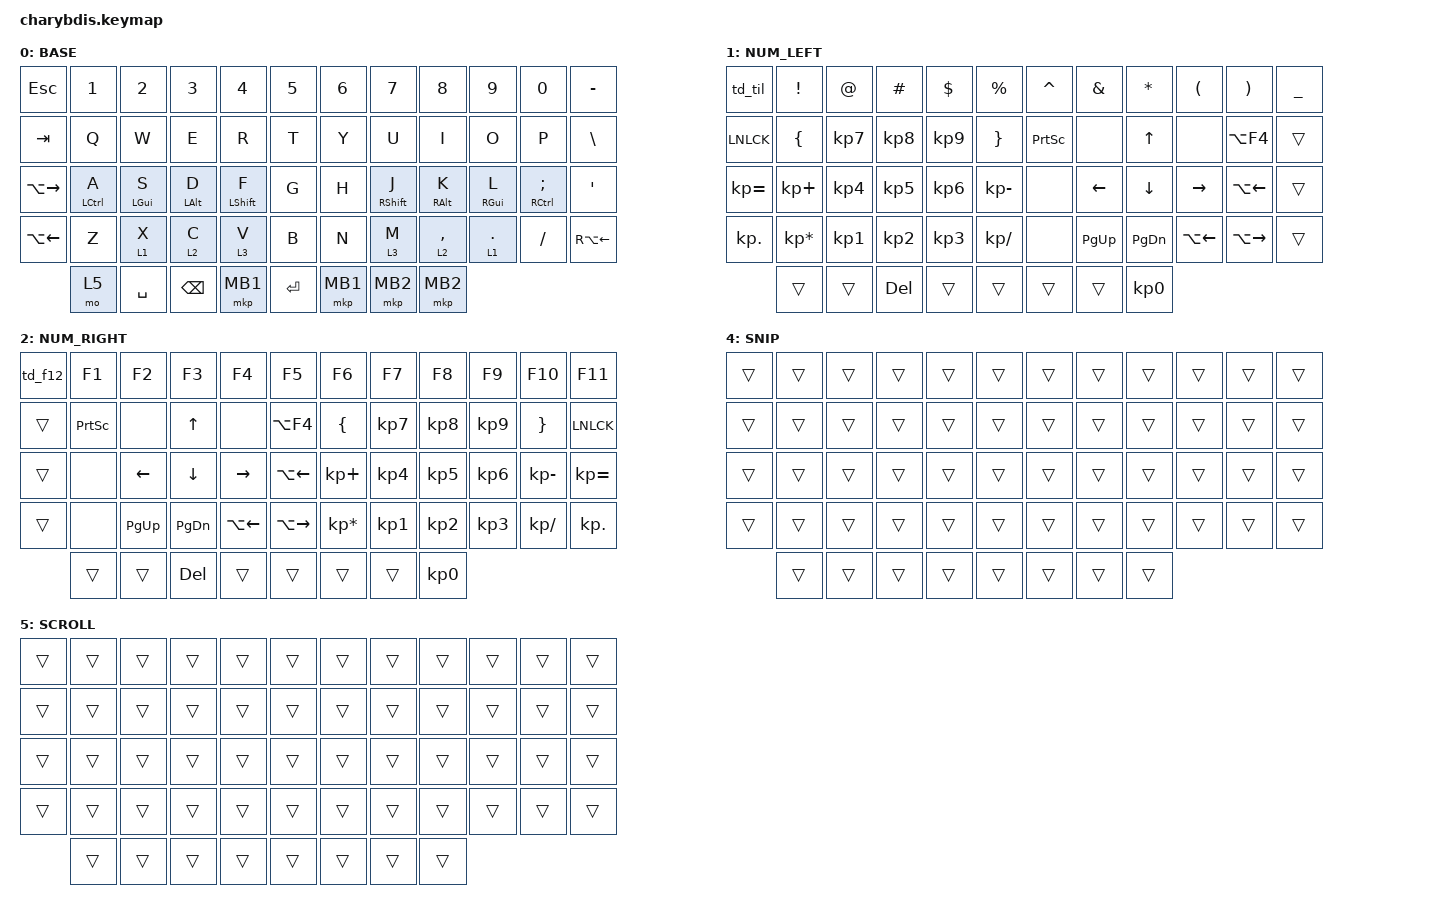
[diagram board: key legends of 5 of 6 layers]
#include <behaviors.dtsi>
#include <dt-bindings/zmk/bt.h>
#include <dt-bindings/zmk/keys.h>
#include <dt-bindings/zmk/outputs.h>
#include <dt-bindings/zmk/pointing.h>
#include <dt-bindings/zmk/input_transform.h>
#include <input/processors.dtsi>

/* Global settings */
&mt {
    quick-tap-ms = <200>;
    flavor = "tap-preferred";
    tapping-term-ms = <170>;
};

&lt {
    quick-tap-ms = <200>;
    flavor = "tap-preferred";
    tapping-term-ms = <170>;
};

/ {
    chosen { zmk,matrix_transform = &default_transform; };

    macros {
        endash: endash {
            compatible = "zmk,behavior-macro";
            #binding-cells = <0>;
            wait-ms = <10>;
            tap-ms = <10>;
            bindings
                = <&macro_press &kp LALT>
                , <&macro_tap &kp KP_N0 &kp KP_N1 &kp KP_N5 &kp KP_N0>
                , <&macro_release &kp LALT>;
        };
    };

    behaviors {
        td_esc: td_esc {
            compatible = "zmk,behavior-tap-dance";
            #binding-cells = <0>;
            tapping-term-ms = <200>;
            bindings = <&kp ESC>, <&to 0>;
        };
        td_til: td_til {
            compatible = "zmk,behavior-tap-dance";
            #binding-cells = <0>;
            tapping-term-ms = <200>;
            bindings = <&kp TILD>, <&to 0>;
        };
        td_f12: td_f12 {
            compatible = "zmk,behavior-tap-dance";
            #binding-cells = <0>;
            tapping-term-ms = <200>;
            bindings = <&kp F12>, <&to 0>;
        };
    };

    combos {
        compatible = "zmk,combos";
        combo_to_layer_1 {
            timeout-ms = <50>;
            key-positions = <38 45>; 
            bindings = <&to 1>;
        };
        combo_to_layer_2 {
            timeout-ms = <50>;
            key-positions = <39 44>; 
            bindings = <&to 2>;
        };
        combo_to_layer_3 {
            timeout-ms = <50>;
            key-positions = <40 43>; 
            bindings = <&to 3>;
        };
    };

#ifdef KEYMAP_DRAW_TRACKBALL
    trackball_listener {
        compatible = "zmk,input-listener";
        device = <&trackball>;
        snipe_override {
            layers = <4>;
            input-processors = <&zip_xy_scaler 1 2>; 
        };
        scroll_override {
            layers = <5>;
            input-processors = <&zip_xy_to_scroll_mapper>;
        };
    };
#endif

    keymap {
        compatible = "zmk,keymap";

        BASE {
            bindings = <
&kp ESC  &kp N1  &kp N2  &kp N3  &kp N4  &kp N5      &kp N6  &kp N7  &kp N8  &kp N9   &kp N0  &kp MINUS
&kp TAB  &kp Q  &kp W  &kp E  &kp R  &kp T      &kp Y  &kp U  &kp I  &kp O  &kp P  &kp BSLH
&kp LA(RIGHT)  &mt LCTRL A  &mt LGUI S  &mt LALT D  &mt LSHIFT F  &kp G      &kp H  &mt RSHIFT J  &mt RALT K  &mt RGUI L  &mt RCTRL SEMI  &kp APOS
&kp LA(LEFT)  &kp Z  &lt 1 X  &lt 2 C  &lt 3 V  &kp B      &kp N  &lt 3 M  &lt 2 COMMA  &lt 1 DOT  &kp SLASH  &kp RA(LEFT)
            &mo 5  &kp SPACE  &kp BSPC  &mkp MB1  &kp ENTER      &mkp MB1  &mkp MB2  &mkp MB2
            >;
        };

        NUM_LEFT {
            bindings = <
&td_til    &kp EXCL    &kp AT      &kp HASH    &kp DLLR    &kp PRCNT   &kp CARET   &kp AMPS    &kp ASTRK   &kp LPAR    &kp RPAR    &kp UNDER
&kp LNLCK  &kp LBRC    &kp KP_N7   &kp KP_N8   &kp KP_N9   &kp RBRC    &kp PSCRN   &none       &kp UP      &none       &kp LA(F4)  &trans
&kp KP_EQUAL &kp KP_PLUS &kp KP_N4 &kp KP_N5   &kp KP_N6   &kp KP_MINUS &none      &kp LEFT    &kp DOWN    &kp RIGHT   &kp LA(LEFT) &trans
&kp KP_DOT &kp KP_MULTIPLY &kp KP_N1 &kp KP_N2 &kp KP_N3   &kp KP_DIVIDE &none     &kp PG_UP   &kp PG_DN   &kp LA(LEFT) &kp LA(RIGHT) &trans
           &trans      &trans      &kp DEL     &trans      &trans      &trans      &trans      &kp KP_N0
            >;
        };

        NUM_RIGHT {
            bindings = <
&td_f12    &kp F1      &kp F2      &kp F3      &kp F4      &kp F5      &kp F6      &kp F7      &kp F8      &kp F9      &kp F10     &kp F11
&trans     &kp PSCRN   &none       &kp UP      &none       &kp LA(F4)  &kp LBRC    &kp KP_N7   &kp KP_N8   &kp KP_N9   &kp RBRC    &kp LNLCK
&trans     &none       &kp LEFT    &kp DOWN    &kp RIGHT   &kp LA(LEFT) &kp KP_PLUS &kp KP_N4   &kp KP_N5   &kp KP_N6   &kp KP_MINUS &kp KP_EQUAL
&trans     &none       &kp PG_UP   &kp PG_DN   &kp LA(LEFT) &kp LA(RIGHT) &kp KP_MULTIPLY &kp KP_N1   &kp KP_N2   &kp KP_N3   &kp KP_DIVIDE &kp KP_DOT
           &trans      &trans      &kp DEL     &trans      &trans      &trans      &trans      &kp KP_N0
            >;
        };

        ADJ {
            bindings = <
&td_esc    &trans      &trans      &trans      &trans      &trans      &trans      &trans      &trans      &trans      &trans      &endash
&trans     &kp DEL     &trans      &none       &none       &kp LC(F4)  &trans      &none       &none       &trans      &trans      &trans
&trans     &trans      &trans      &trans      &trans      &kp LA(LEFT) &trans     &trans      &trans      &trans      &trans      &trans
&trans     &trans      &mo 5       &mo 4       &kp LA(LEFT) &kp LA(RIGHT) &trans   &trans      &mo 4       &mo 5       &mkp MB3    &trans
            >;
        };

        SNIP {
            bindings = <
&trans  &trans  &trans  &trans  &trans  &trans          &trans  &trans    &trans    &trans    &trans  &trans
&trans  &trans  &trans  &trans  &trans  &trans          &trans  &trans    &trans    &trans    &trans  &trans
&trans  &trans  &trans  &trans  &trans  &trans          &trans  &trans    &trans    &trans    &trans  &trans
&trans  &trans  &trans  &trans  &trans  &trans          &trans  &trans    &trans    &trans    &trans  &trans
        &trans  &trans  &trans  &trans  &trans          &trans  &trans  &trans
            >;
        };

        SCROLL {
            bindings = <
&trans  &trans  &trans  &trans  &trans  &trans          &trans  &trans    &trans    &trans    &trans  &trans
&trans  &trans  &trans  &trans  &trans  &trans          &trans  &trans    &trans    &trans    &trans  &trans
&trans  &trans  &trans  &trans  &trans  &trans          &trans  &trans    &trans    &trans    &trans  &trans
&trans  &trans  &trans  &trans  &trans  &trans          &trans  &trans    &trans    &trans    &trans  &trans
        &trans  &trans  &trans  &trans  &trans          &trans  &trans  &trans
            >;
        };
    };
};
